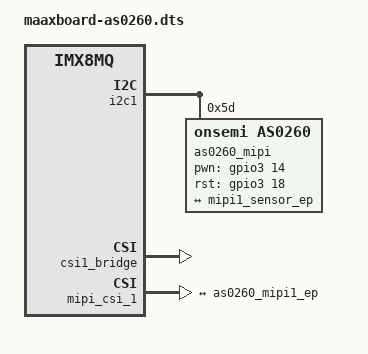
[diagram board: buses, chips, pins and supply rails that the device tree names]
/*
 * Copyright 2021 AVNET
 *
 * This program is free software; you can redistribute it and/or
 * modify it under the terms of the GNU General Public License
 * as published by the Free Software Foundation; either version 2
 * of the License, or (at your option) any later version.
 *
 * This program is distributed in the hope that it will be useful,
 * but WITHOUT ANY WARRANTY; without even the implied warranty of
 * MERCHANTABILITY or FITNESS FOR A PARTICULAR PURPOSE.  See the
 * GNU General Public License for more details.
 */

/dts-v1/;
/plugin/;

#include <dt-bindings/clock/imx8mq-clock.h>
#include <dt-bindings/gpio/gpio.h>

/ {
	compatible = "avnet/embest,maaxboard", "fsl,imx8mq";

	fragment@0 {
		target = <&i2c1>;
		__overlay__ {
			#address-cells = <1>;
			#size-cells = <0>;
            as0260_mipi: as0260_mipi@5d {
				compatible = "onsemi,as0260";
				reg = <0x5d>;
				pinctrl-names = "default";
				pinctrl-0 = <&pinctrl_csi1>;
				clocks = <&clk IMX8MQ_CLK_CLKO2>;
				clock-names = "csi_mclk";
				csi_id = <0>;
				pwn-gpios = <&gpio3 14 GPIO_ACTIVE_HIGH>;
				rst-gpios = <&gpio3 18 GPIO_ACTIVE_HIGH>;
				status = "okay";

				mclk = <27000000>;
				mclk_source = <0>;
				port {
					as0260_mipi1_ep: endpoint {
						remote-endpoint = <&mipi1_sensor_ep>;
					};
				};
			};
		};
	};
	
	fragment@1 {
		target = <&csi1_bridge>;
		__overlay__ {
			status = "okay";
		};
	};

	fragment@2 {
		target = <&mipi_csi_1>;
		__overlay__ {
			status = "okay";
			port {
				mipi1_sensor_ep: endpoint@0 {
					remote-endpoint = <&as0260_mipi1_ep>;
					data-lanes = <1 2>;
					bus-type = <4>;
				};
			};
		};
	};	
};
